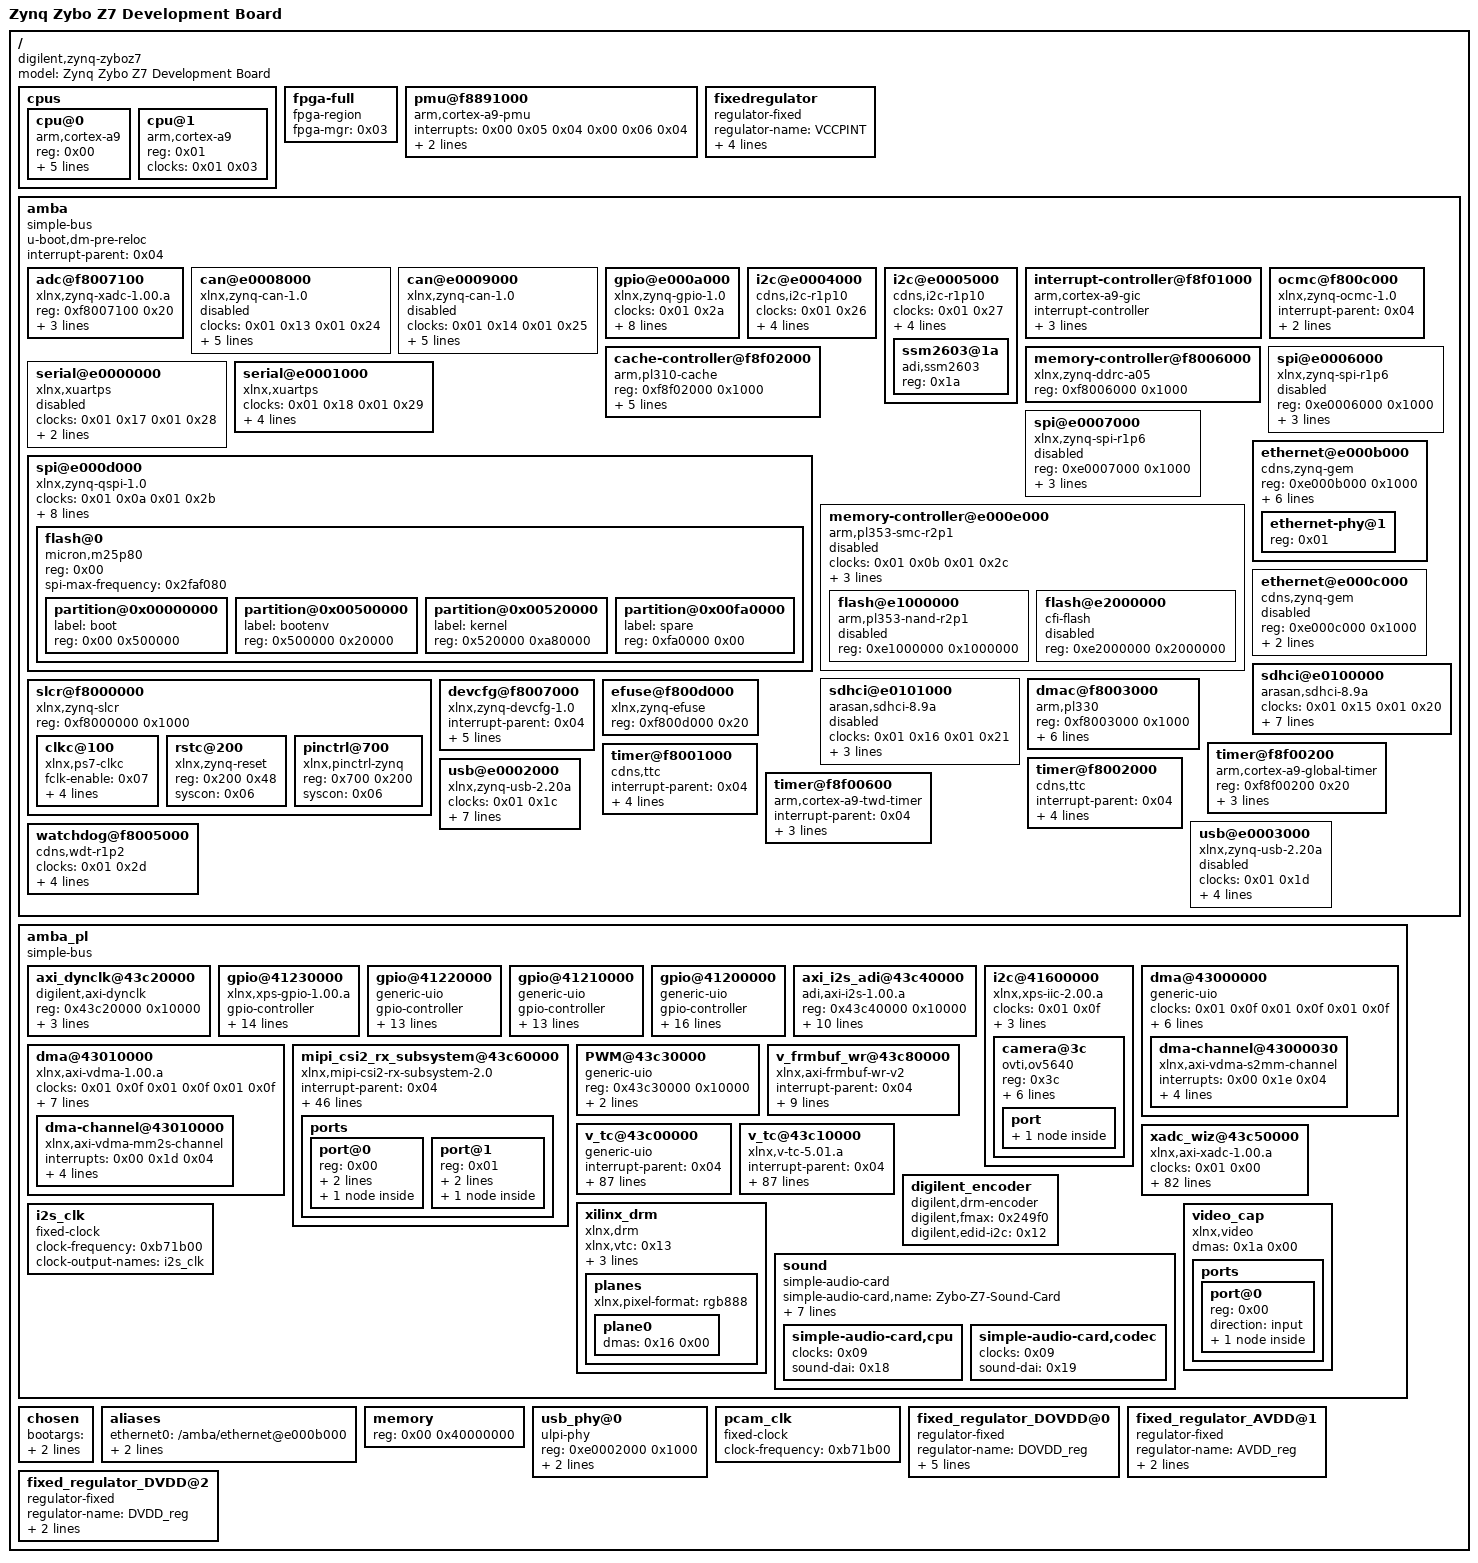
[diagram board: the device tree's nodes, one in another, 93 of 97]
/dts-v1/;

/ {
	#address-cells = <0x01>;
	#size-cells = <0x01>;
	compatible = "digilent,zynq-zyboz7\0xlnx,zynq-7000";
	model = "Zynq Zybo Z7 Development Board";

	cpus {
		#address-cells = <0x01>;
		#size-cells = <0x00>;

		cpu@0 {
			compatible = "arm,cortex-a9";
			device_type = "cpu";
			reg = <0x00>;
			clocks = <0x01 0x03>;
			clock-latency = <0x3e8>;
			cpu0-supply = <0x02>;
			operating-points = <0xa2c2a 0xf4240 0x51615 0xf4240>;
		};

		cpu@1 {
			compatible = "arm,cortex-a9";
			device_type = "cpu";
			reg = <0x01>;
			clocks = <0x01 0x03>;
		};
	};

	fpga-full {
		compatible = "fpga-region";
		fpga-mgr = <0x03>;
		#address-cells = <0x01>;
		#size-cells = <0x01>;
		ranges;
	};

	pmu@f8891000 {
		compatible = "arm,cortex-a9-pmu";
		interrupts = <0x00 0x05 0x04 0x00 0x06 0x04>;
		interrupt-parent = <0x04>;
		reg = <0xf8891000 0x1000 0xf8893000 0x1000>;
	};

	fixedregulator {
		compatible = "regulator-fixed";
		regulator-name = "VCCPINT";
		regulator-min-microvolt = <0xf4240>;
		regulator-max-microvolt = <0xf4240>;
		regulator-boot-on;
		regulator-always-on;
		linux,phandle = <0x02>;
		phandle = <0x02>;
	};

	amba {
		u-boot,dm-pre-reloc;
		compatible = "simple-bus";
		#address-cells = <0x01>;
		#size-cells = <0x01>;
		interrupt-parent = <0x04>;
		ranges;

		adc@f8007100 {
			compatible = "xlnx,zynq-xadc-1.00.a";
			reg = <0xf8007100 0x20>;
			interrupts = <0x00 0x07 0x04>;
			interrupt-parent = <0x04>;
			clocks = <0x01 0x0c>;
		};

		can@e0008000 {
			compatible = "xlnx,zynq-can-1.0";
			status = "disabled";
			clocks = <0x01 0x13 0x01 0x24>;
			clock-names = "can_clk\0pclk";
			reg = <0xe0008000 0x1000>;
			interrupts = <0x00 0x1c 0x04>;
			interrupt-parent = <0x04>;
			tx-fifo-depth = <0x40>;
			rx-fifo-depth = <0x40>;
		};

		can@e0009000 {
			compatible = "xlnx,zynq-can-1.0";
			status = "disabled";
			clocks = <0x01 0x14 0x01 0x25>;
			clock-names = "can_clk\0pclk";
			reg = <0xe0009000 0x1000>;
			interrupts = <0x00 0x33 0x04>;
			interrupt-parent = <0x04>;
			tx-fifo-depth = <0x40>;
			rx-fifo-depth = <0x40>;
		};

		gpio@e000a000 {
			compatible = "xlnx,zynq-gpio-1.0";
			#gpio-cells = <0x02>;
			clocks = <0x01 0x2a>;
			gpio-controller;
			interrupt-controller;
			#interrupt-cells = <0x02>;
			interrupt-parent = <0x04>;
			interrupts = <0x00 0x14 0x04>;
			reg = <0xe000a000 0x1000>;
			emio-gpio-width = <0x40>;
			gpio-mask-high = <0x00>;
			gpio-mask-low = <0x5600>;
			linux,phandle = <0x07>;
			phandle = <0x07>;
		};

		i2c@e0004000 {
			compatible = "cdns,i2c-r1p10";
			status = "okay";
			clocks = <0x01 0x26>;
			interrupt-parent = <0x04>;
			interrupts = <0x00 0x19 0x04>;
			reg = <0xe0004000 0x1000>;
			#address-cells = <0x01>;
			#size-cells = <0x00>;
			clock-frequency = <0x186a0>;
			linux,phandle = <0x12>;
			phandle = <0x12>;
		};

		i2c@e0005000 {
			compatible = "cdns,i2c-r1p10";
			status = "okay";
			clocks = <0x01 0x27>;
			interrupt-parent = <0x04>;
			interrupts = <0x00 0x30 0x04>;
			reg = <0xe0005000 0x1000>;
			#address-cells = <0x01>;
			#size-cells = <0x00>;
			clock-frequency = <0x61a80>;

			ssm2603@1a {
				#sound-dai-cells = <0x00>;
				compatible = "adi,ssm2603";
				reg = <0x1a>;
				linux,phandle = <0x19>;
				phandle = <0x19>;
			};
		};

		interrupt-controller@f8f01000 {
			compatible = "arm,cortex-a9-gic";
			#interrupt-cells = <0x03>;
			interrupt-controller;
			reg = <0xf8f01000 0x1000 0xf8f00100 0x100>;
			num_cpus = <0x02>;
			num_interrupts = <0x60>;
			linux,phandle = <0x04>;
			phandle = <0x04>;
		};

		cache-controller@f8f02000 {
			compatible = "arm,pl310-cache";
			reg = <0xf8f02000 0x1000>;
			interrupts = <0x00 0x02 0x04>;
			arm,data-latency = <0x03 0x02 0x02>;
			arm,tag-latency = <0x02 0x02 0x02>;
			cache-unified;
			cache-level = <0x02>;
		};

		memory-controller@f8006000 {
			compatible = "xlnx,zynq-ddrc-a05";
			reg = <0xf8006000 0x1000>;
		};

		ocmc@f800c000 {
			compatible = "xlnx,zynq-ocmc-1.0";
			interrupt-parent = <0x04>;
			interrupts = <0x00 0x03 0x04>;
			reg = <0xf800c000 0x1000>;
		};

		serial@e0000000 {
			compatible = "xlnx,xuartps\0cdns,uart-r1p8";
			status = "disabled";
			clocks = <0x01 0x17 0x01 0x28>;
			clock-names = "uart_clk\0pclk";
			reg = <0xe0000000 0x1000>;
			interrupts = <0x00 0x1b 0x04>;
		};

		serial@e0001000 {
			compatible = "xlnx,xuartps\0cdns,uart-r1p8";
			status = "okay";
			clocks = <0x01 0x18 0x01 0x29>;
			clock-names = "uart_clk\0pclk";
			reg = <0xe0001000 0x1000>;
			interrupts = <0x00 0x32 0x04>;
			device_type = "serial";
			port-number = <0x00>;
			u-boot,dm-pre-reloc;
		};

		spi@e0006000 {
			compatible = "xlnx,zynq-spi-r1p6";
			reg = <0xe0006000 0x1000>;
			status = "disabled";
			interrupt-parent = <0x04>;
			interrupts = <0x00 0x1a 0x04>;
			clocks = <0x01 0x19 0x01 0x22>;
			clock-names = "ref_clk\0pclk";
			#address-cells = <0x01>;
			#size-cells = <0x00>;
		};

		spi@e0007000 {
			compatible = "xlnx,zynq-spi-r1p6";
			reg = <0xe0007000 0x1000>;
			status = "disabled";
			interrupt-parent = <0x04>;
			interrupts = <0x00 0x31 0x04>;
			clocks = <0x01 0x1a 0x01 0x23>;
			clock-names = "ref_clk\0pclk";
			#address-cells = <0x01>;
			#size-cells = <0x00>;
		};

		spi@e000d000 {
			clock-names = "ref_clk\0pclk";
			clocks = <0x01 0x0a 0x01 0x2b>;
			compatible = "xlnx,zynq-qspi-1.0";
			status = "okay";
			interrupt-parent = <0x04>;
			interrupts = <0x00 0x13 0x04>;
			reg = <0xe000d000 0x1000>;
			#address-cells = <0x01>;
			#size-cells = <0x00>;
			is-dual = <0x00>;
			num-cs = <0x01>;
			spi-rx-bus-width = <0x04>;
			spi-tx-bus-width = <0x04>;
			u-boot,dm-pre-reloc;

			flash@0 {
				compatible = "micron,m25p80\0s25fl128s\0spi-flash";
				reg = <0x00>;
				#address-cells = <0x01>;
				#size-cells = <0x01>;
				spi-max-frequency = <0x2faf080>;

				partition@0x00000000 {
					label = "boot";
					reg = <0x00 0x500000>;
				};

				partition@0x00500000 {
					label = "bootenv";
					reg = <0x500000 0x20000>;
				};

				partition@0x00520000 {
					label = "kernel";
					reg = <0x520000 0xa80000>;
				};

				partition@0x00fa0000 {
					label = "spare";
					reg = <0xfa0000 0x00>;
				};
			};
		};

		memory-controller@e000e000 {
			#address-cells = <0x01>;
			#size-cells = <0x01>;
			status = "disabled";
			clock-names = "memclk\0aclk";
			clocks = <0x01 0x0b 0x01 0x2c>;
			compatible = "arm,pl353-smc-r2p1";
			interrupt-parent = <0x04>;
			interrupts = <0x00 0x12 0x04>;
			ranges;
			reg = <0xe000e000 0x1000>;

			flash@e1000000 {
				status = "disabled";
				compatible = "arm,pl353-nand-r2p1";
				reg = <0xe1000000 0x1000000>;
				#address-cells = <0x01>;
				#size-cells = <0x01>;
			};

			flash@e2000000 {
				status = "disabled";
				compatible = "cfi-flash";
				reg = <0xe2000000 0x2000000>;
				#address-cells = <0x01>;
				#size-cells = <0x01>;
			};
		};

		ethernet@e000b000 {
			compatible = "cdns,zynq-gem\0cdns,gem";
			reg = <0xe000b000 0x1000>;
			status = "okay";
			interrupts = <0x00 0x16 0x04>;
			clocks = <0x01 0x1e 0x01 0x1e 0x01 0x0d>;
			clock-names = "pclk\0hclk\0tx_clk";
			#address-cells = <0x01>;
			#size-cells = <0x00>;
			phy-mode = "rgmii-id";
			xlnx,ptp-enet-clock = <0x69f6bcb>;
			local-mac-address;
			phy-handle = <0x05>;

			ethernet-phy@1 {
				reg = <0x01>;
				device_type = "ethernet-phy";
				linux,phandle = <0x05>;
				phandle = <0x05>;
			};
		};

		ethernet@e000c000 {
			compatible = "cdns,zynq-gem\0cdns,gem";
			reg = <0xe000c000 0x1000>;
			status = "disabled";
			interrupts = <0x00 0x2d 0x04>;
			clocks = <0x01 0x1f 0x01 0x1f 0x01 0x0e>;
			clock-names = "pclk\0hclk\0tx_clk";
			#address-cells = <0x01>;
			#size-cells = <0x00>;
		};

		sdhci@e0100000 {
			compatible = "arasan,sdhci-8.9a";
			status = "okay";
			clock-names = "clk_xin\0clk_ahb";
			clocks = <0x01 0x15 0x01 0x20>;
			interrupt-parent = <0x04>;
			interrupts = <0x00 0x18 0x04>;
			reg = <0xe0100000 0x1000>;
			xlnx,has-cd = <0x01>;
			xlnx,has-power = <0x00>;
			xlnx,has-wp = <0x00>;
			u-boot,dm-pre-reloc;
		};

		sdhci@e0101000 {
			compatible = "arasan,sdhci-8.9a";
			status = "disabled";
			clock-names = "clk_xin\0clk_ahb";
			clocks = <0x01 0x16 0x01 0x21>;
			interrupt-parent = <0x04>;
			interrupts = <0x00 0x2f 0x04>;
			reg = <0xe0101000 0x1000>;
		};

		slcr@f8000000 {
			#address-cells = <0x01>;
			#size-cells = <0x01>;
			compatible = "xlnx,zynq-slcr\0syscon\0simple-mfd";
			reg = <0xf8000000 0x1000>;
			ranges;
			linux,phandle = <0x06>;
			phandle = <0x06>;

			clkc@100 {
				#clock-cells = <0x01>;
				compatible = "xlnx,ps7-clkc";
				fclk-enable = <0x07>;
				clock-output-names = "armpll\0ddrpll\0iopll\0cpu_6or4x\0cpu_3or2x\0cpu_2x\0cpu_1x\0ddr2x\0ddr3x\0dci\0lqspi\0smc\0pcap\0gem0\0gem1\0fclk0\0fclk1\0fclk2\0fclk3\0can0\0can1\0sdio0\0sdio1\0uart0\0uart1\0spi0\0spi1\0dma\0usb0_aper\0usb1_aper\0gem0_aper\0gem1_aper\0sdio0_aper\0sdio1_aper\0spi0_aper\0spi1_aper\0can0_aper\0can1_aper\0i2c0_aper\0i2c1_aper\0uart0_aper\0uart1_aper\0gpio_aper\0lqspi_aper\0smc_aper\0swdt\0dbg_trc\0dbg_apb";
				reg = <0x100 0x100>;
				ps-clk-frequency = <0x1fca055>;
				linux,phandle = <0x01>;
				phandle = <0x01>;
			};

			rstc@200 {
				compatible = "xlnx,zynq-reset";
				reg = <0x200 0x48>;
				#reset-cells = <0x01>;
				syscon = <0x06>;
			};

			pinctrl@700 {
				compatible = "xlnx,pinctrl-zynq";
				reg = <0x700 0x200>;
				syscon = <0x06>;
			};
		};

		dmac@f8003000 {
			compatible = "arm,pl330\0arm,primecell";
			reg = <0xf8003000 0x1000>;
			interrupt-parent = <0x04>;
			interrupt-names = "abort\0dma0\0dma1\0dma2\0dma3\0dma4\0dma5\0dma6\0dma7";
			interrupts = <0x00 0x0d 0x04 0x00 0x0e 0x04 0x00 0x0f 0x04 0x00 0x10 0x04 0x00 0x11 0x04 0x00 0x28 0x04 0x00 0x29 0x04 0x00 0x2a 0x04 0x00 0x2b 0x04>;
			#dma-cells = <0x01>;
			#dma-channels = <0x08>;
			#dma-requests = <0x04>;
			clocks = <0x01 0x1b>;
			clock-names = "apb_pclk";
			linux,phandle = <0x0a>;
			phandle = <0x0a>;
		};

		devcfg@f8007000 {
			compatible = "xlnx,zynq-devcfg-1.0";
			interrupt-parent = <0x04>;
			interrupts = <0x00 0x08 0x04>;
			reg = <0xf8007000 0x100>;
			clocks = <0x01 0x0c 0x01 0x0f 0x01 0x10 0x01 0x11 0x01 0x12>;
			clock-names = "ref_clk\0fclk0\0fclk1\0fclk2\0fclk3";
			syscon = <0x06>;
			linux,phandle = <0x03>;
			phandle = <0x03>;
		};

		efuse@f800d000 {
			compatible = "xlnx,zynq-efuse";
			reg = <0xf800d000 0x20>;
		};

		timer@f8f00200 {
			compatible = "arm,cortex-a9-global-timer";
			reg = <0xf8f00200 0x20>;
			interrupts = <0x01 0x0b 0x301>;
			interrupt-parent = <0x04>;
			clocks = <0x01 0x04>;
		};

		timer@f8001000 {
			interrupt-parent = <0x04>;
			interrupts = <0x00 0x0a 0x04 0x00 0x0b 0x04 0x00 0x0c 0x04>;
			compatible = "cdns,ttc";
			clocks = <0x01 0x06>;
			reg = <0xf8001000 0x1000>;
		};

		timer@f8002000 {
			interrupt-parent = <0x04>;
			interrupts = <0x00 0x25 0x04 0x00 0x26 0x04 0x00 0x27 0x04>;
			compatible = "cdns,ttc";
			clocks = <0x01 0x06>;
			reg = <0xf8002000 0x1000>;
		};

		timer@f8f00600 {
			interrupt-parent = <0x04>;
			interrupts = <0x01 0x0d 0x301>;
			compatible = "arm,cortex-a9-twd-timer";
			reg = <0xf8f00600 0x20>;
			clocks = <0x01 0x04>;
		};

		usb@e0002000 {
			compatible = "xlnx,zynq-usb-2.20a\0chipidea,usb2";
			status = "okay";
			clocks = <0x01 0x1c>;
			interrupt-parent = <0x04>;
			interrupts = <0x00 0x15 0x04>;
			reg = <0xe0002000 0x1000>;
			phy_type = "ulpi";
			usb-reset = <0x07 0x2e 0x00>;
			dr_mode = "host";
			usb-phy = <0x08>;
		};

		usb@e0003000 {
			compatible = "xlnx,zynq-usb-2.20a\0chipidea,usb2";
			status = "disabled";
			clocks = <0x01 0x1d>;
			interrupt-parent = <0x04>;
			interrupts = <0x00 0x2c 0x04>;
			reg = <0xe0003000 0x1000>;
			phy_type = "ulpi";
		};

		watchdog@f8005000 {
			clocks = <0x01 0x2d>;
			compatible = "cdns,wdt-r1p2";
			interrupt-parent = <0x04>;
			interrupts = <0x00 0x09 0x01>;
			reg = <0xf8005000 0x1000>;
			timeout-sec = <0x0a>;
		};
	};

	amba_pl {
		#address-cells = <0x01>;
		#size-cells = <0x01>;
		compatible = "simple-bus";
		ranges;

		axi_dynclk@43c20000 {
			compatible = "digilent,axi-dynclk";
			reg = <0x43c20000 0x10000>;
			xlnx,s00-axi-addr-width = <0x05>;
			xlnx,s00-axi-data-width = <0x20>;
			#clock-cells = <0x00>;
			clocks = <0x01 0x0f>;
			linux,phandle = <0x15>;
			phandle = <0x15>;
		};

		gpio@41230000 {
			#gpio-cells = <0x03>;
			compatible = "xlnx,xps-gpio-1.00.a";
			gpio-controller;
			reg = <0x41230000 0x10000>;
			xlnx,all-inputs = <0x00>;
			xlnx,all-inputs-2 = <0x00>;
			xlnx,all-outputs = <0x00>;
			xlnx,all-outputs-2 = <0x00>;
			xlnx,dout-default = <0x00>;
			xlnx,dout-default-2 = <0x00>;
			xlnx,gpio-width = <0x01>;
			xlnx,gpio2-width = <0x20>;
			xlnx,interrupt-present = <0x00>;
			xlnx,is-dual = <0x00>;
			xlnx,tri-default = <0xffffffff>;
			xlnx,tri-default-2 = <0xffffffff>;
			clock-names = "s_axi_aclk";
			clocks = <0x01 0x0f>;
		};

		gpio@41220000 {
			#gpio-cells = <0x02>;
			compatible = "generic-uio";
			gpio-controller;
			reg = <0x41220000 0x10000>;
			xlnx,all-inputs = <0x00>;
			xlnx,all-inputs-2 = <0x00>;
			xlnx,all-outputs = <0x00>;
			xlnx,all-outputs-2 = <0x00>;
			xlnx,dout-default = <0x00>;
			xlnx,dout-default-2 = <0x00>;
			xlnx,gpio-width = <0x04>;
			xlnx,gpio2-width = <0x20>;
			xlnx,interrupt-present = <0x00>;
			xlnx,is-dual = <0x00>;
			xlnx,tri-default = <0xffffffff>;
			xlnx,tri-default-2 = <0xffffffff>;
		};

		gpio@41210000 {
			#gpio-cells = <0x02>;
			compatible = "generic-uio";
			gpio-controller;
			reg = <0x41210000 0x10000>;
			xlnx,all-inputs = <0x01>;
			xlnx,all-inputs-2 = <0x01>;
			xlnx,all-outputs = <0x00>;
			xlnx,all-outputs-2 = <0x00>;
			xlnx,dout-default = <0x00>;
			xlnx,dout-default-2 = <0x00>;
			xlnx,gpio-width = <0x04>;
			xlnx,gpio2-width = <0x04>;
			xlnx,interrupt-present = <0x00>;
			xlnx,is-dual = <0x01>;
			xlnx,tri-default = <0xffffffff>;
			xlnx,tri-default-2 = <0xffffffff>;
		};

		gpio@41200000 {
			#gpio-cells = <0x02>;
			#interrupt-cells = <0x02>;
			compatible = "generic-uio";
			gpio-controller;
			interrupt-controller;
			interrupt-parent = <0x04>;
			interrupts = <0x00 0x21 0x04>;
			reg = <0x41200000 0x10000>;
			xlnx,all-inputs = <0x00>;
			xlnx,all-inputs-2 = <0x01>;
			xlnx,all-outputs = <0x01>;
			xlnx,all-outputs-2 = <0x00>;
			xlnx,dout-default = <0x00>;
			xlnx,dout-default-2 = <0x00>;
			xlnx,gpio-width = <0x01>;
			xlnx,gpio2-width = <0x01>;
			xlnx,interrupt-present = <0x01>;
			xlnx,is-dual = <0x01>;
			xlnx,tri-default = <0xffffffff>;
			xlnx,tri-default-2 = <0xffffffff>;
		};

		axi_i2s_adi@43c40000 {
			compatible = "adi,axi-i2s-1.00.a";
			reg = <0x43c40000 0x10000>;
			xlnx,bclk-pol = <0x00>;
			xlnx,dma-type = <0x01>;
			xlnx,has-rx = <0x01>;
			xlnx,has-tx = <0x01>;
			xlnx,lrclk-pol = <0x00>;
			xlnx,num-ch = <0x01>;
			xlnx,s-axi-min-size = <0x1ff>;
			xlnx,slot-width = <0x18>;
			#sound-dai-cells = <0x00>;
			clocks = <0x01 0x0f 0x09>;
			clock-names = "axi\0ref";
			dmas = <0x0a 0x00 0x0a 0x01>;
			dma-names = "tx\0rx";
			linux,phandle = <0x18>;
			phandle = <0x18>;
		};

		i2c@41600000 {
			#address-cells = <0x01>;
			#size-cells = <0x00>;
			clock-names = "ref_clk";
			clocks = <0x01 0x0f>;
			compatible = "xlnx,xps-iic-2.00.a";
			interrupt-parent = <0x04>;
			interrupts = <0x00 0x34 0x04>;
			reg = <0x41600000 0x10000>;

			camera@3c {
				compatible = "ovti,ov5640";
				reg = <0x3c>;
				clocks = <0x0b>;
				clock-names = "xclk";
				DOVDD-supply = <0x0c>;
				AVDD-supply = <0x0d>;
				DVDD-supply = <0x0e>;
				powerdown-gpios = <0x07 0x3a 0x00>;
				reset-gpios = <0x07 0x3b 0x01>;

				port {

					endpoint {
						remote-endpoint = <0x0f>;
						clock-lanes = <0x00>;
						data-lanes = <0x01 0x02>;
						linux,phandle = <0x11>;
						phandle = <0x11>;
					};
				};
			};
		};

		dma@43000000 {
			#dma-cells = <0x01>;
			clock-names = "s_axi_lite_aclk\0m_axi_s2mm_aclk\0m_axi_s2mm_aclk";
			clocks = <0x01 0x0f 0x01 0x0f 0x01 0x0f>;
			compatible = "generic-uio";
			interrupt-parent = <0x04>;
			interrupts = <0x00 0x1e 0x04>;
			reg = <0x43000000 0x10000>;
			xlnx,addrwidth = <0x20>;
			xlnx,flush-fsync = <0x01>;
			xlnx,num-fstores = <0x01>;

			dma-channel@43000030 {
				compatible = "xlnx,axi-vdma-s2mm-channel";
				interrupts = <0x00 0x1e 0x04>;
				xlnx,datawidth = <0x18>;
				xlnx,device-id = <0x00>;
				xlnx,genlock-mode;
				xlnx,include-dre;
			};
		};

		dma@43010000 {
			#dma-cells = <0x01>;
			clock-names = "s_axi_lite_aclk\0m_axi_mm2s_aclk\0m_axi_mm2s_aclk";
			clocks = <0x01 0x0f 0x01 0x0f 0x01 0x0f>;
			compatible = "xlnx,axi-vdma-1.00.a";
			interrupt-parent = <0x04>;
			interrupts = <0x00 0x1d 0x04>;
			reg = <0x43010000 0x10000>;
			xlnx,addrwidth = <0x20>;
			xlnx,flush-fsync = <0x01>;
			xlnx,num-fstores = <0x01>;
			dma-ranges = <0x00 0x00 0x40000000>;
			linux,phandle = <0x16>;
			phandle = <0x16>;

			dma-channel@43010000 {
				compatible = "xlnx,axi-vdma-mm2s-channel";
				interrupts = <0x00 0x1d 0x04>;
				xlnx,datawidth = <0x18>;
				xlnx,device-id = <0x01>;
				xlnx,genlock-mode;
				xlnx,include-dre;
			};
		};

		mipi_csi2_rx_subsystem@43c60000 {
			compatible = "xlnx,mipi-csi2-rx-subsystem-2.0";
			interrupt-parent = <0x04>;
			interrupts = <0x00 0x23 0x04>;
			reg = <0x43c60000 0x20000>;
			xlnx,cal-mode = "FIXED";
			xlnx,clk-lane-io-position = <0x00>;
			xlnx,csi-en-activelanes = "false";
			xlnx,csi-en-crc = "true";
			xlnx,csi-filter-userdatatype = "false";
			xlnx,csi-opt1-regs = "false";
			xlnx,csi2rx-dbg = <0x00>;
			xlnx,data-lane0-io-position = <0x02>;
			xlnx,data-lane1-io-position = <0x04>;
			xlnx,data-lane2-io-position = <0x06>;
			xlnx,data-lane3-io-position = <0x08>;
			xlnx,dphy-lanes = <0x02>;
			xlnx,dphy-mode = "SLAVE";
			xlnx,en-bg0-pin0 = "false";
			xlnx,en-bg0-pin6 = "false";
			xlnx,en-bg1-pin0 = "false";
			xlnx,en-bg1-pin6 = "false";
			xlnx,en-bg2-pin0 = "false";
			xlnx,en-bg2-pin6 = "false";
			xlnx,en-bg3-pin0 = "false";
			xlnx,en-bg3-pin6 = "false";
			xlnx,en-clk300m = "false";
			xlnx,exdes-board = "ZCU102";
			xlnx,exdes-config = "MIPI_Video_Pipe_Camera_to_Display";
			xlnx,exdes-fmc = "LI-IMX274MIPI-FMC V1.0 Single Sensor";
			xlnx,hs-line-rate = <0x320>;
			xlnx,hs-settle-ns = <0x93>;
			xlnx,idly-group-name = "mipi_csi2rx_idly_group";
			xlnx,idly-tap = <0x02>;
			xlnx,init = <0x186a0>;
			xlnx,is-7series = "true";
			xlnx,mipi-slv-int = <0x00>;
			xlnx,share-idlyctrl = "true";
			clocks = <0x01 0x0f>;
			xlnx,max-lanes = <0x02>;
			xlnx,dphy-present;
			xlnx,vc = <0x04>;
			xlnx,csi-pxl-format = "YUV422_8bit";
			xlnx,vfb;
			xlnx,ppc = <0x01>;
			xlnx,axis-tdata-width = <0x10>;
			reset-gpios = <0x07 0x39 0x01>;

			ports {
				#address-cells = <0x01>;
				#size-cells = <0x00>;

				port@0 {
					reg = <0x00>;
					xlnx,video-format = <0x00>;
					xlnx,video-width = <0x08>;

					endpoint {
						remote-endpoint = <0x10>;
						linux,phandle = <0x1b>;
						phandle = <0x1b>;
					};
				};

				port@1 {
					reg = <0x01>;
					xlnx,video-format = <0x00>;
					xlnx,video-width = <0x08>;

					endpoint {
						data-lanes = <0x01 0x02>;
						remote-endpoint = <0x11>;
						linux,phandle = <0x0f>;
						phandle = <0x0f>;
					};
				};
			};
		};

		PWM@43c30000 {
			compatible = "generic-uio";
			reg = <0x43c30000 0x10000>;
			xlnx,pwm-axi-addr-width = <0x07>;
			xlnx,pwm-axi-data-width = <0x20>;
		};

		v_frmbuf_wr@43c80000 {
			compatible = "xlnx,axi-frmbuf-wr-v2";
			interrupt-parent = <0x04>;
			interrupts = <0x00 0x24 0x04>;
			reg = <0x43c80000 0x10000>;
			xlnx,s-axi-ctrl-addr-width = <0x07>;
			xlnx,s-axi-ctrl-data-width = <0x20>;
			#dma-cells = <0x01>;
			clocks = <0x01 0x0f>;
			clock-names = "axis";
			reset-gpios = <0x07 0x36 0x01>;
			xlnx,dma-addr-width = <0x20>;
			xlnx,vid-formats = "yuyv\0uyvy\0nv16";
			xlnx,pixels-per-clock = <0x01>;
			linux,phandle = <0x1a>;
			phandle = <0x1a>;
		};

		v_tc@43c00000 {
			compatible = "generic-uio";
			interrupt-parent = <0x04>;
			interrupts = <0x00 0x20 0x04>;
			reg = <0x43c00000 0x10000>;
			xlnx,det-achroma-en = <0x00>;
			xlnx,det-avideo-en = <0x01>;
			xlnx,det-fieldid-en = <0x00>;
			xlnx,det-hblank-en = <0x00>;
			xlnx,det-hsync-en = <0x01>;
			xlnx,det-vblank-en = <0x00>;
			xlnx,det-vsync-en = <0x01>;
			xlnx,detect-en = <0x01>;
			xlnx,fsync-hstart0 = <0x00>;
			xlnx,fsync-hstart1 = <0x00>;
			xlnx,fsync-hstart10 = <0x00>;
			xlnx,fsync-hstart11 = <0x00>;
			xlnx,fsync-hstart12 = <0x00>;
			xlnx,fsync-hstart13 = <0x00>;
			xlnx,fsync-hstart14 = <0x00>;
			xlnx,fsync-hstart15 = <0x00>;
			xlnx,fsync-hstart2 = <0x00>;
			xlnx,fsync-hstart3 = <0x00>;
			xlnx,fsync-hstart4 = <0x00>;
			xlnx,fsync-hstart5 = <0x00>;
			xlnx,fsync-hstart6 = <0x00>;
			xlnx,fsync-hstart7 = <0x00>;
			xlnx,fsync-hstart8 = <0x00>;
			xlnx,fsync-hstart9 = <0x00>;
			xlnx,fsync-vstart0 = <0x00>;
			xlnx,fsync-vstart1 = <0x00>;
			xlnx,fsync-vstart10 = <0x00>;
			xlnx,fsync-vstart11 = <0x00>;
			xlnx,fsync-vstart12 = <0x00>;
			xlnx,fsync-vstart13 = <0x00>;
			xlnx,fsync-vstart14 = <0x00>;
			xlnx,fsync-vstart15 = <0x00>;
			xlnx,fsync-vstart2 = <0x00>;
			xlnx,fsync-vstart3 = <0x00>;
			xlnx,fsync-vstart4 = <0x00>;
			xlnx,fsync-vstart5 = <0x00>;
			xlnx,fsync-vstart6 = <0x00>;
			xlnx,fsync-vstart7 = <0x00>;
			xlnx,fsync-vstart8 = <0x00>;
			xlnx,fsync-vstart9 = <0x00>;
			xlnx,gen-achroma-en = <0x00>;
			xlnx,gen-achroma-polarity = <0x01>;
			xlnx,gen-auto-switch = <0x00>;
			xlnx,gen-avideo-en = <0x01>;
			xlnx,gen-avideo-polarity = <0x01>;
			xlnx,gen-cparity = <0x00>;
			xlnx,gen-f0-vblank-hend = <0x500>;
			xlnx,gen-f0-vblank-hstart = <0x500>;
			xlnx,gen-f0-vframe-size = <0x2ee>;
			xlnx,gen-f0-vsync-hend = <0x500>;
			xlnx,gen-f0-vsync-hstart = <0x500>;
			xlnx,gen-f0-vsync-vend = <0x2d9>;
			xlnx,gen-f0-vsync-vstart = <0x2d4>;
			xlnx,gen-f1-vblank-hend = <0x500>;
			xlnx,gen-f1-vblank-hstart = <0x500>;
			xlnx,gen-f1-vframe-size = <0x2ee>;
			xlnx,gen-f1-vsync-hend = <0x500>;
			xlnx,gen-f1-vsync-hstart = <0x500>;
			xlnx,gen-f1-vsync-vend = <0x2d9>;
			xlnx,gen-f1-vsync-vstart = <0x2d4>;
			xlnx,gen-fieldid-en = <0x00>;
			xlnx,gen-fieldid-polarity = <0x01>;
			xlnx,gen-hactive-size = <0x500>;
			xlnx,gen-hblank-en = <0x01>;
			xlnx,gen-hblank-polarity = <0x01>;
			xlnx,gen-hframe-size = <0x672>;
			xlnx,gen-hsync-en = <0x01>;
			xlnx,gen-hsync-end = <0x596>;
			xlnx,gen-hsync-polarity = <0x01>;
			xlnx,gen-hsync-start = <0x56e>;
			xlnx,gen-interlaced = <0x00>;
			xlnx,gen-vactive-size = <0x2d0>;
			xlnx,gen-vblank-en = <0x01>;
			xlnx,gen-vblank-polarity = <0x01>;
			xlnx,gen-video-format = <0x02>;
			xlnx,gen-vsync-en = <0x01>;
			xlnx,gen-vsync-polarity = <0x01>;
			xlnx,generate-en = <0x00>;
			xlnx,has-axi4-lite = <0x01>;
			xlnx,has-intc-if = <0x01>;
			xlnx,interlace-en = <0x00>;
			xlnx,max-lines = <0x1000>;
			xlnx,max-pixels = <0x1000>;
			xlnx,num-fsyncs = <0x01>;
			xlnx,sync-en = <0x00>;
		};

		v_tc@43c10000 {
			compatible = "xlnx,v-tc-5.01.a";
			interrupt-parent = <0x04>;
			interrupts = <0x00 0x1f 0x04>;
			reg = <0x43c10000 0x10000>;
			xlnx,det-achroma-en = <0x00>;
			xlnx,det-avideo-en = <0x01>;
			xlnx,det-fieldid-en = <0x00>;
			xlnx,det-hblank-en = <0x01>;
			xlnx,det-hsync-en = <0x01>;
			xlnx,det-vblank-en = <0x01>;
			xlnx,det-vsync-en = <0x01>;
			xlnx,detect-en = <0x00>;
			xlnx,fsync-hstart0 = <0x00>;
			xlnx,fsync-hstart1 = <0x00>;
			xlnx,fsync-hstart10 = <0x00>;
			xlnx,fsync-hstart11 = <0x00>;
			xlnx,fsync-hstart12 = <0x00>;
			xlnx,fsync-hstart13 = <0x00>;
			xlnx,fsync-hstart14 = <0x00>;
			xlnx,fsync-hstart15 = <0x00>;
			xlnx,fsync-hstart2 = <0x00>;
			xlnx,fsync-hstart3 = <0x00>;
			xlnx,fsync-hstart4 = <0x00>;
			xlnx,fsync-hstart5 = <0x00>;
			xlnx,fsync-hstart6 = <0x00>;
			xlnx,fsync-hstart7 = <0x00>;
			xlnx,fsync-hstart8 = <0x00>;
			xlnx,fsync-hstart9 = <0x00>;
			xlnx,fsync-vstart0 = <0x00>;
			xlnx,fsync-vstart1 = <0x00>;
			xlnx,fsync-vstart10 = <0x00>;
			xlnx,fsync-vstart11 = <0x00>;
			xlnx,fsync-vstart12 = <0x00>;
			xlnx,fsync-vstart13 = <0x00>;
			xlnx,fsync-vstart14 = <0x00>;
			xlnx,fsync-vstart15 = <0x00>;
			xlnx,fsync-vstart2 = <0x00>;
			xlnx,fsync-vstart3 = <0x00>;
			xlnx,fsync-vstart4 = <0x00>;
			xlnx,fsync-vstart5 = <0x00>;
			xlnx,fsync-vstart6 = <0x00>;
			xlnx,fsync-vstart7 = <0x00>;
			xlnx,fsync-vstart8 = <0x00>;
			xlnx,fsync-vstart9 = <0x00>;
			xlnx,gen-achroma-en = <0x00>;
			xlnx,gen-achroma-polarity = <0x01>;
			xlnx,gen-auto-switch = <0x00>;
			xlnx,gen-avideo-en = <0x01>;
			xlnx,gen-avideo-polarity = <0x01>;
			xlnx,gen-cparity = <0x00>;
			xlnx,gen-f0-vblank-hend = <0x500>;
			xlnx,gen-f0-vblank-hstart = <0x500>;
			xlnx,gen-f0-vframe-size = <0x2ee>;
			xlnx,gen-f0-vsync-hend = <0x500>;
			xlnx,gen-f0-vsync-hstart = <0x500>;
			xlnx,gen-f0-vsync-vend = <0x2d9>;
			xlnx,gen-f0-vsync-vstart = <0x2d4>;
			xlnx,gen-f1-vblank-hend = <0x500>;
			xlnx,gen-f1-vblank-hstart = <0x500>;
			xlnx,gen-f1-vframe-size = <0x2ee>;
			xlnx,gen-f1-vsync-hend = <0x500>;
			xlnx,gen-f1-vsync-hstart = <0x500>;
			xlnx,gen-f1-vsync-vend = <0x2d9>;
			xlnx,gen-f1-vsync-vstart = <0x2d4>;
			xlnx,gen-fieldid-en = <0x00>;
			xlnx,gen-fieldid-polarity = <0x01>;
			xlnx,gen-hactive-size = <0x500>;
			xlnx,gen-hblank-en = <0x01>;
			xlnx,gen-hblank-polarity = <0x01>;
			xlnx,gen-hframe-size = <0x672>;
			xlnx,gen-hsync-en = <0x01>;
			xlnx,gen-hsync-end = <0x596>;
			xlnx,gen-hsync-polarity = <0x01>;
			xlnx,gen-hsync-start = <0x56e>;
			xlnx,gen-interlaced = <0x00>;
			xlnx,gen-vactive-size = <0x2d0>;
			xlnx,gen-vblank-en = <0x01>;
			xlnx,gen-vblank-polarity = <0x01>;
			xlnx,gen-video-format = <0x02>;
			xlnx,gen-vsync-en = <0x01>;
			xlnx,gen-vsync-polarity = <0x01>;
			xlnx,generate-en = <0x01>;
			xlnx,has-axi4-lite = <0x01>;
			xlnx,has-intc-if = <0x00>;
			xlnx,interlace-en = <0x00>;
			xlnx,max-lines = <0x1000>;
			xlnx,max-pixels = <0x1000>;
			xlnx,num-fsyncs = <0x01>;
			xlnx,sync-en = <0x00>;
			linux,phandle = <0x13>;
			phandle = <0x13>;
		};

		xadc_wiz@43c50000 {
			clock-names = "ref_clk";
			clocks = <0x01 0x00>;
			compatible = "xlnx,axi-xadc-1.00.a";
			interrupt-parent = <0x04>;
			interrupts = <0x00 0x22 0x04>;
			reg = <0x43c50000 0x10000>;
			xlnx,alarm-limit-r0 = <0xb5ed>;
			xlnx,alarm-limit-r1 = <0x57e4>;
			xlnx,alarm-limit-r10 = <0x5555>;
			xlnx,alarm-limit-r11 = <0x5111>;
			xlnx,alarm-limit-r12 = <0x9999>;
			xlnx,alarm-limit-r13 = <0x91eb>;
			xlnx,alarm-limit-r14 = <0x6aaa>;
			xlnx,alarm-limit-r15 = <0x6666>;
			xlnx,alarm-limit-r2 = <0xa147>;
			xlnx,alarm-limit-r3 = <0xca33>;
			xlnx,alarm-limit-r4 = <0xa93a>;
			xlnx,alarm-limit-r5 = <0x52c6>;
			xlnx,alarm-limit-r6 = <0x9555>;
			xlnx,alarm-limit-r7 = <0xae4e>;
			xlnx,alarm-limit-r8 = <0x5999>;
			xlnx,alarm-limit-r9 = <0x5111>;
			xlnx,configuration-r0 = <0x1000>;
			xlnx,configuration-r1 = <0x21af>;
			xlnx,configuration-r2 = <0x400>;
			xlnx,dclk-frequency = <0x64>;
			xlnx,external-mux = "none";
			xlnx,external-mux-channel = "VP_VN";
			xlnx,external-muxaddr-enable = <0x00>;
			xlnx,fifo-depth = <0x07>;
			xlnx,has-axi = <0x01>;
			xlnx,has-axi4stream = <0x00>;
			xlnx,has-busy = <0x01>;
			xlnx,has-channel = <0x01>;
			xlnx,has-convst = <0x00>;
			xlnx,has-convstclk = <0x00>;
			xlnx,has-dclk = <0x01>;
			xlnx,has-drp = <0x00>;
			xlnx,has-eoc = <0x01>;
			xlnx,has-eos = <0x01>;
			xlnx,has-external-mux = <0x00>;
			xlnx,has-jtagbusy = <0x00>;
			xlnx,has-jtaglocked = <0x00>;
			xlnx,has-jtagmodified = <0x00>;
			xlnx,has-ot-alarm = <0x00>;
			xlnx,has-reset = <0x00>;
			xlnx,has-temp-bus = <0x00>;
			xlnx,has-user-temp-alarm = <0x00>;
			xlnx,has-vbram-alarm = <0x00>;
			xlnx,has-vccaux-alarm = <0x00>;
			xlnx,has-vccddro-alarm = <0x00>;
			xlnx,has-vccint-alarm = <0x00>;
			xlnx,has-vccpaux-alarm = <0x00>;
			xlnx,has-vccpint-alarm = <0x00>;
			xlnx,has-vn = <0x01>;
			xlnx,has-vp = <0x01>;
			xlnx,include-intr = <0x01>;
			xlnx,sampling-rate = "961538.4615384615";
			xlnx,sequence-r0 = <0x77e1>;
			xlnx,sequence-r1 = <0xc0c0>;
			xlnx,sequence-r2 = <0x00>;
			xlnx,sequence-r3 = <0x00>;
			xlnx,sequence-r4 = <0x00>;
			xlnx,sequence-r5 = <0x00>;
			xlnx,sequence-r6 = <0x00>;
			xlnx,sequence-r7 = <0x00>;
			xlnx,sim-file-name = "design";
			xlnx,sim-file-rel-path = "./";
			xlnx,sim-file-sel = "Default";
			xlnx,vaux0 = <0x00>;
			xlnx,vaux1 = <0x00>;
			xlnx,vaux10 = <0x00>;
			xlnx,vaux11 = <0x00>;
			xlnx,vaux12 = <0x00>;
			xlnx,vaux13 = <0x00>;
			xlnx,vaux14 = <0x01>;
			xlnx,vaux15 = <0x01>;
			xlnx,vaux2 = <0x00>;
			xlnx,vaux3 = <0x00>;
			xlnx,vaux4 = <0x00>;
			xlnx,vaux5 = <0x00>;
			xlnx,vaux6 = <0x01>;
			xlnx,vaux7 = <0x01>;
			xlnx,vaux8 = <0x00>;
			xlnx,vaux9 = <0x00>;
		};

		digilent_encoder {
			compatible = "digilent,drm-encoder";
			digilent,fmax = <0x249f0>;
			digilent,edid-i2c = <0x12>;
			linux,phandle = <0x14>;
			phandle = <0x14>;
		};

		xilinx_drm {
			compatible = "xlnx,drm";
			xlnx,vtc = <0x13>;
			xlnx,connector-type = "HDMIA";
			xlnx,encoder-slave = <0x14>;
			clocks = <0x15>;

			planes {
				xlnx,pixel-format = "rgb888";

				plane0 {
					dmas = <0x16 0x00>;
					dma-names = "dma0";
				};
			};
		};

		i2s_clk {
			#clock-cells = <0x00>;
			compatible = "fixed-clock";
			clock-frequency = <0xb71b00>;
			clock-output-names = "i2s_clk";
			linux,phandle = <0x09>;
			phandle = <0x09>;
		};

		sound {
			compatible = "simple-audio-card";
			simple-audio-card,name = "Zybo-Z7-Sound-Card";
			simple-audio-card,format = "i2s";
			simple-audio-card,bitclock-master = <0x17>;
			simple-audio-card,frame-master = <0x17>;
			simple-audio-card,widgets = "Microphone\0Microphone Jack\0Headphone\0Headphone Jack\0Line\0Line In Jack";
			simple-audio-card,routing = "MICIN\0Microphone Jack\0Headphone Jack\0LHPOUT\0Headphone Jack\0RHPOUT\0LLINEIN\0Line In Jack\0RLINEIN\0Line In Jack";

			simple-audio-card,cpu {
				clocks = <0x09>;
				sound-dai = <0x18>;
				linux,phandle = <0x17>;
				phandle = <0x17>;
			};

			simple-audio-card,codec {
				clocks = <0x09>;
				sound-dai = <0x19>;
			};
		};

		video_cap {
			compatible = "xlnx,video";
			dmas = <0x1a 0x00>;
			dma-names = "port0";

			ports {
				#address-cells = <0x01>;
				#size-cells = <0x00>;

				port@0 {
					reg = <0x00>;
					direction = "input";

					endpoint {
						remote-endpoint = <0x1b>;
						linux,phandle = <0x10>;
						phandle = <0x10>;
					};
				};
			};
		};
	};

	chosen {
		bootargs = "console=ttyPS0,115200 earlyprintk uio_pdrv_genirq.of_id=generic-uio root=/dev/mmcblk0p2 rw rootwait";
		stdout-path = "serial0:115200n8";
	};

	aliases {
		ethernet0 = "/amba/ethernet@e000b000";
		serial0 = "/amba/serial@e0001000";
		spi0 = "/amba/spi@e000d000";
	};

	memory {
		device_type = "memory";
		reg = <0x00 0x40000000>;
	};

	usb_phy@0 {
		compatible = "ulpi-phy";
		#phy-cells = <0x00>;
		reg = <0xe0002000 0x1000>;
		view-port = <0x170>;
		drv-vbus;
		linux,phandle = <0x08>;
		phandle = <0x08>;
	};

	pcam_clk {
		#clock-cells = <0x00>;
		compatible = "fixed-clock";
		clock-frequency = <0xb71b00>;
		linux,phandle = <0x0b>;
		phandle = <0x0b>;
	};

	fixed_regulator_DOVDD@0 {
		compatible = "regulator-fixed";
		regulator-name = "DOVDD_reg";
		regulator-min-microvolt = <0x1b7740>;
		regulator-max-microvolt = <0x1b7740>;
		gpio = <0x07 0x38 0x00>;
		startup-delay-us = <0xc350>;
		enable-active-high;
		linux,phandle = <0x0c>;
		phandle = <0x0c>;
	};

	fixed_regulator_AVDD@1 {
		compatible = "regulator-fixed";
		regulator-name = "AVDD_reg";
		regulator-min-microvolt = <0x2ab980>;
		regulator-max-microvolt = <0x2ab980>;
		linux,phandle = <0x0d>;
		phandle = <0x0d>;
	};

	fixed_regulator_DVDD@2 {
		compatible = "regulator-fixed";
		regulator-name = "DVDD_reg";
		regulator-min-microvolt = <0x16e360>;
		regulator-max-microvolt = <0x16e360>;
		linux,phandle = <0x0e>;
		phandle = <0x0e>;
	};
};
